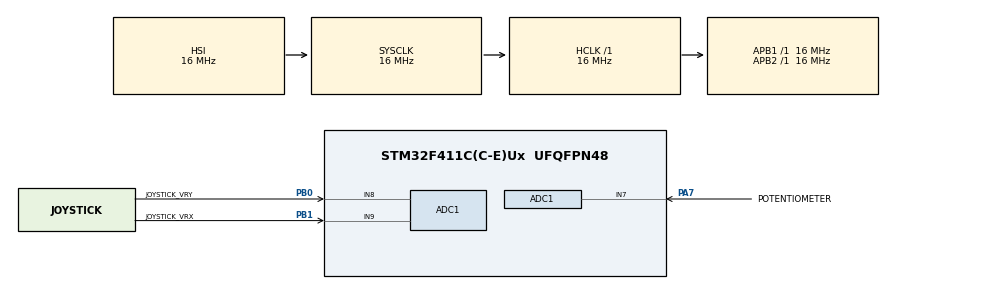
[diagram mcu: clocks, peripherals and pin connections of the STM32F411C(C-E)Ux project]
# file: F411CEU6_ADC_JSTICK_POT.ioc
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ADC1.Channel-0\#ChannelRegularConversion=ADC_CHANNEL_9
ADC1.Channel-1\#ChannelRegularConversion=ADC_CHANNEL_8
ADC1.Channel-2\#ChannelRegularConversion=ADC_CHANNEL_7
ADC1.NbrOfConversion=3
ADC1.NbrOfConversionFlag=1
ADC1.Rank-0\#ChannelRegularConversion=1
ADC1.Rank-1\#ChannelRegularConversion=2
ADC1.Rank-2\#ChannelRegularConversion=3
ADC1.SamplingTime-0\#ChannelRegularConversion=ADC_SAMPLETIME_28CYCLES
ADC1.SamplingTime-1\#ChannelRegularConversion=ADC_SAMPLETIME_84CYCLES
ADC1.SamplingTime-2\#ChannelRegularConversion=ADC_SAMPLETIME_112CYCLES
ADC1.ScanConvMode=ENABLE
ADC1.master=1
Mcu.Family=STM32F4
Mcu.Name=STM32F411C(C-E)Ux
Mcu.Package=UFQFPN48
NVIC.PriorityGroup=NVIC_PRIORITYGROUP_4
PA13.Mode=Serial_Wire
PA13.Signal=SYS_JTMS-SWDIO
PA14.Mode=Serial_Wire
PA14.Signal=SYS_JTCK-SWCLK
PA7.GPIO_Label=POTENTIOMETER
PA7.Signal=ADCx_IN7
PB0.GPIO_Label=JOYSTICK_VRY
PB0.Signal=ADCx_IN8
PB1.GPIO_Label=JOYSTICK_VRX
PB1.Signal=ADCx_IN9
ProjectManager.HeapSize=0x200
ProjectManager.StackSize=0x400
ProjectManager.TargetToolchain=STM32CubeIDE
RCC.AHBFreq_Value=16000000
RCC.APB1Freq_Value=16000000
RCC.APB2Freq_Value=16000000
RCC.CortexFreq_Value=16000000
RCC.HSE_VALUE=25000000
RCC.HSI_VALUE=16000000
RCC.LSE_VALUE=32768
RCC.SYSCLKFreq_VALUE=16000000
RCC.VCOOutputFreq_Value=192000000
SH.ADCx_IN7.0=ADC1_IN7,IN7
SH.ADCx_IN8.0=ADC1_IN8,IN8
SH.ADCx_IN9.0=ADC1_IN9,IN9
board=custom

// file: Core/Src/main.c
/* USER CODE BEGIN Header */
/**
  ******************************************************************************
  * @file           : main.c
  * @brief          : Main program body
  ******************************************************************************
  * @attention
  *
  * Copyright (c) 2024 STMicroelectronics.
  * All rights reserved.
  *
  * This software is licensed under terms that can be found in the LICENSE file
  * in the root directory of this software component.
  * If no LICENSE file comes with this software, it is provided AS-IS.
  *
  ******************************************************************************
  */
/* USER CODE END Header */
#include "main.h"

ADC_HandleTypeDef hadc1;

/* USER CODE BEGIN PV */
uint32_t joystickX = 0, joystickY = 0, potentiometer = 0;
/* USER CODE END PV */

void SystemClock_Config(void);
static void MX_GPIO_Init(void);
static void MX_ADC1_Init(void);

/* USER CODE BEGIN 0 */
#define ADC_CH_JOYSTICK_X    9
#define ADC_CH_JOYSTICK_Y    8
#define ADC_CH_POTENTIOMETER 7

void ADC_Select_Channel(int ch) {
	ADC_ChannelConfTypeDef sConfig = {0};

	// The selected channel must be given rank 1!
	// Otherwise, the highest rank channel will get reflected to other channels.
	sConfig.Rank = 1;

	// The code is extracted from autogenerated code in MX_ADC1_Init()
	switch (ch) {
	case 7:
		sConfig.Channel = ADC_CHANNEL_7;
		sConfig.SamplingTime = ADC_SAMPLETIME_112CYCLES;
		break;

	case 8:
		sConfig.Channel = ADC_CHANNEL_8;
		sConfig.SamplingTime = ADC_SAMPLETIME_84CYCLES;
		break;

	case 9:
		sConfig.Channel = ADC_CHANNEL_9;
		sConfig.SamplingTime = ADC_SAMPLETIME_28CYCLES;
		break;

	default:
		// Error
		break;
	}

	if (HAL_ADC_ConfigChannel(&hadc1, &sConfig) != HAL_OK)
	{
		Error_Handler();
	}
}
/* USER CODE END 0 */

int main(void)
{

  /* MCU Configuration--------------------------------------------------------*/

  /* Reset of all peripherals, Initializes the Flash interface and the Systick. */
  HAL_Init();

  /* Configure the system clock */
  SystemClock_Config();

  /* Initialize all configured peripherals */
  MX_GPIO_Init();
  MX_ADC1_Init();

  /* Infinite loop */
  while (1)
  {

    /* USER CODE BEGIN 3 */
	// Get ADC value
	ADC_Select_Channel(ADC_CH_JOYSTICK_X);
	HAL_ADC_Start(&hadc1);
	HAL_ADC_PollForConversion(&hadc1, 1000);
	joystickX = HAL_ADC_GetValue(&hadc1);
	HAL_ADC_Stop(&hadc1);

	ADC_Select_Channel(ADC_CH_JOYSTICK_Y);
	HAL_ADC_Start(&hadc1);
	HAL_ADC_PollForConversion(&hadc1, 1000);
	joystickY = HAL_ADC_GetValue(&hadc1);
	HAL_ADC_Stop(&hadc1);

	ADC_Select_Channel(ADC_CH_POTENTIOMETER);
	HAL_ADC_Start(&hadc1);
	HAL_ADC_PollForConversion(&hadc1, 1000);
	potentiometer = HAL_ADC_GetValue(&hadc1);
	HAL_ADC_Stop(&hadc1);

	// Pretend we have to do something else for a while
	HAL_Delay(100);
  }
  /* USER CODE END 3 */
}

void SystemClock_Config(void)
{
  RCC_OscInitTypeDef RCC_OscInitStruct = {0};
  RCC_ClkInitTypeDef RCC_ClkInitStruct = {0};

  /** Configure the main internal regulator output voltage
  */
  __HAL_RCC_PWR_CLK_ENABLE();
  __HAL_PWR_VOLTAGESCALING_CONFIG(PWR_REGULATOR_VOLTAGE_SCALE1);

  /** Initializes the RCC Oscillators according to the specified parameters
  * in the RCC_OscInitTypeDef structure.
  */
  RCC_OscInitStruct.OscillatorType = RCC_OSCILLATORTYPE_HSI;
  RCC_OscInitStruct.HSIState = RCC_HSI_ON;
  RCC_OscInitStruct.HSICalibrationValue = RCC_HSICALIBRATION_DEFAULT;
  RCC_OscInitStruct.PLL.PLLState = RCC_PLL_NONE;
  if (HAL_RCC_OscConfig(&RCC_OscInitStruct) != HAL_OK)
  {
    Error_Handler();
  }

  /** Initializes the CPU, AHB and APB buses clocks
  */
  RCC_ClkInitStruct.ClockType = RCC_CLOCKTYPE_HCLK|RCC_CLOCKTYPE_SYSCLK
                              |RCC_CLOCKTYPE_PCLK1|RCC_CLOCKTYPE_PCLK2;
  RCC_ClkInitStruct.SYSCLKSource = RCC_SYSCLKSOURCE_HSI;
  RCC_ClkInitStruct.AHBCLKDivider = RCC_SYSCLK_DIV1;
  RCC_ClkInitStruct.APB1CLKDivider = RCC_HCLK_DIV1;
  RCC_ClkInitStruct.APB2CLKDivider = RCC_HCLK_DIV1;

  if (HAL_RCC_ClockConfig(&RCC_ClkInitStruct, FLASH_LATENCY_0) != HAL_OK)
  {
    Error_Handler();
  }
}

static void MX_ADC1_Init(void)
{

  ADC_ChannelConfTypeDef sConfig = {0};

  /** Configure the global features of the ADC (Clock, Resolution, Data Alignment and number of conversion)
  */
  hadc1.Instance = ADC1;
  hadc1.Init.ClockPrescaler = ADC_CLOCK_SYNC_PCLK_DIV2;
  hadc1.Init.Resolution = ADC_RESOLUTION_12B;
  hadc1.Init.ScanConvMode = ENABLE;
  hadc1.Init.ContinuousConvMode = DISABLE;
  hadc1.Init.DiscontinuousConvMode = DISABLE;
  hadc1.Init.ExternalTrigConvEdge = ADC_EXTERNALTRIGCONVEDGE_NONE;
  hadc1.Init.ExternalTrigConv = ADC_SOFTWARE_START;
  hadc1.Init.DataAlign = ADC_DATAALIGN_RIGHT;
  hadc1.Init.NbrOfConversion = 1;    // Change from 3 to 1.
  hadc1.Init.DMAContinuousRequests = DISABLE;
  hadc1.Init.EOCSelection = ADC_EOC_SINGLE_CONV;
  if (HAL_ADC_Init(&hadc1) != HAL_OK)
  {
    Error_Handler();
  }

#if 0 // To comment out the remaining configuration
  /** Configure for the selected ADC regular channel its corresponding rank in the sequencer and its sample time.
  */
  sConfig.Channel = ADC_CHANNEL_9;
  sConfig.Rank = 1;
  sConfig.SamplingTime = ADC_SAMPLETIME_28CYCLES;
  if (HAL_ADC_ConfigChannel(&hadc1, &sConfig) != HAL_OK)
  {
    Error_Handler();
  }

  /** Configure for the selected ADC regular channel its corresponding rank in the sequencer and its sample time.
  */
  sConfig.Channel = ADC_CHANNEL_8;
  sConfig.Rank = 2;
  sConfig.SamplingTime = ADC_SAMPLETIME_84CYCLES;
  if (HAL_ADC_ConfigChannel(&hadc1, &sConfig) != HAL_OK)
  {
    Error_Handler();
  }

  /** Configure for the selected ADC regular channel its corresponding rank in the sequencer and its sample time.
  */
  sConfig.Channel = ADC_CHANNEL_7;
  sConfig.Rank = 3;
  sConfig.SamplingTime = ADC_SAMPLETIME_112CYCLES;
  if (HAL_ADC_ConfigChannel(&hadc1, &sConfig) != HAL_OK)
  {
    Error_Handler();
  }
  /* USER CODE BEGIN ADC1_Init 2 */
#endif
  /* USER CODE END ADC1_Init 2 */

}

static void MX_GPIO_Init(void)
{

  /* GPIO Ports Clock Enable */
  __HAL_RCC_GPIOA_CLK_ENABLE();
  __HAL_RCC_GPIOB_CLK_ENABLE();

}

void Error_Handler(void)
{
  __disable_irq();
  while (1)
  {
  }
}
